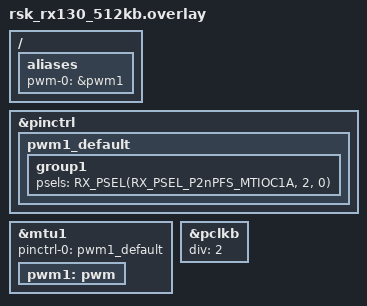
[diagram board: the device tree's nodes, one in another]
/*
 * Copyright (c) 2024 Renesas Electronics Corporation
 *
 * SPDX-License-Identifier: Apache-2.0
 */

/ {
	aliases {
		pwm-0 = &pwm1;
	};
};

&pinctrl {
	pwm1_default: pwm1_default {
		group1 {
			psels = <RX_PSEL(RX_PSEL_P2nPFS_MTIOC1A, 2, 0)>; /* P20 MTIOC1A JA2-PIN22*/
		};
	};
};

&mtu1 {
	status = "okay";
	pinctrl-0 = <&pwm1_default>;
	pinctrl-names = "default";
	pwm1: pwm {
		status = "okay";
	};
};

&pclkb {
	div = <2>;
};
